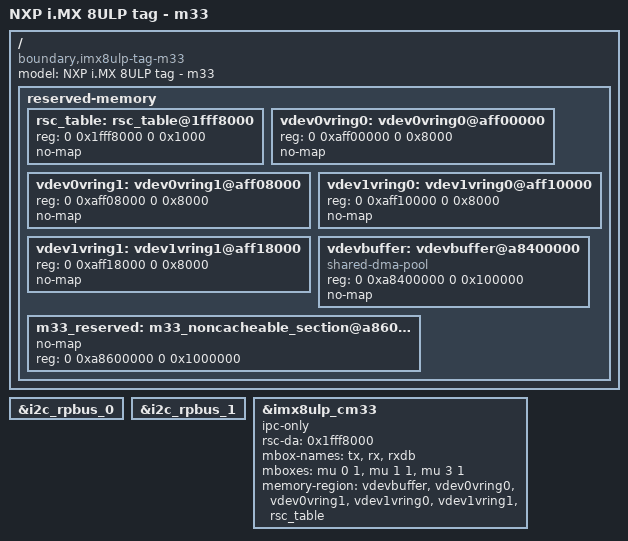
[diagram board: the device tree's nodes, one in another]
// SPDX-License-Identifier: (GPL-2.0 OR MIT)
/*
 * Copyright 2022 Boundary Devices
 */

#include "imx8ulp-tag.dts"
#include "imx8ulp-rpmsg.dtsi"

/ {
	model = "NXP i.MX 8ULP tag - m33";
	compatible = "boundary,imx8ulp-tag-m33", "fsl,imx8ulp";

	reserved-memory {
		rsc_table: rsc_table@1fff8000{
			reg = <0 0x1fff8000 0 0x1000>;
			no-map;
		};

		vdev0vring0: vdev0vring0@aff00000 {
			reg = <0 0xaff00000 0 0x8000>;
			no-map;
		};

		vdev0vring1: vdev0vring1@aff08000 {
			reg = <0 0xaff08000 0 0x8000>;
			no-map;
		};

		vdev1vring0: vdev1vring0@aff10000 {
			reg = <0 0xaff10000 0 0x8000>;
			no-map;
		};

		vdev1vring1: vdev1vring1@aff18000 {
			reg = <0 0xaff18000 0 0x8000>;
			no-map;
		};

		vdevbuffer: vdevbuffer@a8400000 {
			compatible = "shared-dma-pool";
			reg = <0 0xa8400000 0 0x100000>;
			no-map;
		};

		m33_reserved: m33_noncacheable_section@a8600000 {
			no-map;
			reg = <0 0xa8600000 0 0x1000000>;
		};
	};

};

&i2c_rpbus_0 {
	#address-cells = <1>;
	#size-cells = <0>;
	status = "okay";
};

&i2c_rpbus_1 {
	#address-cells = <1>;
	#size-cells = <0>;
	status = "okay";
};

&imx8ulp_cm33 {
	ipc-only;
	rsc-da=<0x1fff8000>;
	mbox-names = "tx", "rx", "rxdb";
	mboxes = <&mu 0 1
			&mu 1 1
			&mu 3 1>;
	memory-region = <&vdevbuffer>, <&vdev0vring0>, <&vdev0vring1>,
			<&vdev1vring0>, <&vdev1vring1>, <&rsc_table>;
	status = "okay";
};
